# CSI_TX_IF0_VBUS2APB_WRAP_VBUSP_APB_CSI2TX register map
Vendor: Texas Instruments
Peripheral module from a debugger description file (folder J7ES).
Registers are 32-bit, read-write, reset 0x0 unless marked. A register's access mark holds for its fields unless they carry their own. Offsets are as the file gives them; lines under a group give offsets from that group; [hi:lo] are bit positions; {n}, {i} and the like mark numbered series; 'fields as' and 'values as' point back to an identical list; <NAME> marks a mode.

## CSI_TX_IF0_VBUS2APB_WRAP_VBUSP_APB_CSI2TX
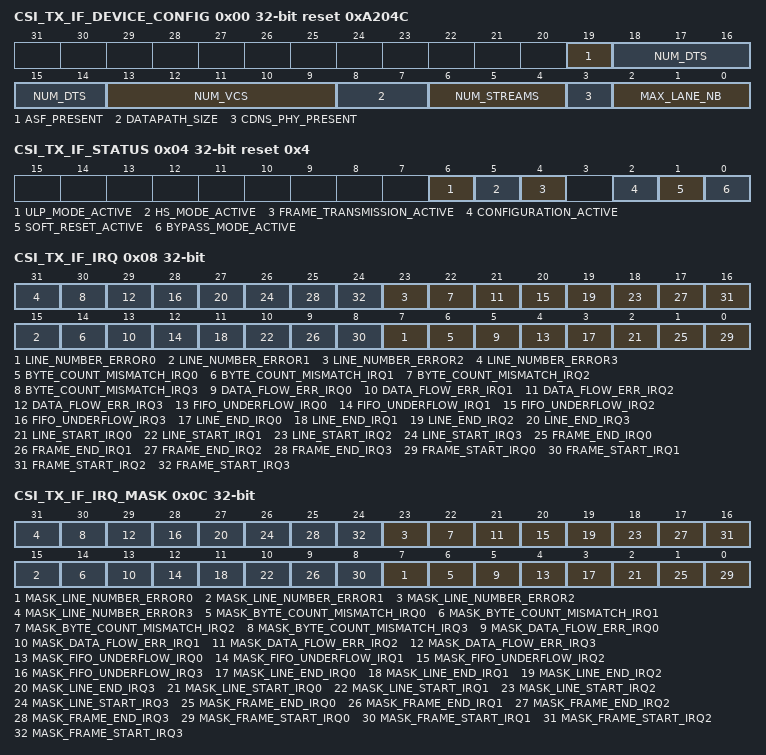
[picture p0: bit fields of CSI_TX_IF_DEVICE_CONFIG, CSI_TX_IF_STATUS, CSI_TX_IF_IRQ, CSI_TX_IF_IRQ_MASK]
0x00 CSI_TX_IF_DEVICE_CONFIG ro reset 0xA204C — CSI2 Transmitter Device Configuration Register
  [19] ASF_PRESENT — Active Internal Diagnostic Features:
  [18:14] NUM_DTS — Number of Datatypes DT_NUMBER=8
  [13:9] NUM_VCS — Number of Virtual Channels VC_NUMBER=16
  [8:7] DATAPATH_SIZE — Internal Datapath width
  [6:4] NUM_STREAMS — Number of Stream interfaces
  [3] CDNS_PHY_PRESENT — DPHY present
  [2:0] MAX_LANE_NB — Max Number of Lanes
0x04 CSI_TX_IF_STATUS ro reset 0x4 — CSI2 Transmitter Status Register
  [6] ULP_MODE_ACTIVE — Ultra Low Power Mode Active Flag When HIGH this bit indicates that ultra low power mode is active.
  [5] HS_MODE_ACTIVE — High Speed Mode Active Flag When HIGH this bit indicates that high speed mode is active.
  [4] FRAME_TRANSMISSION_ACTIVE — Frame Transmission Active Flag When HIGH this bit indicates that frame transmission is active.
  [2] CONFIGURATION_ACTIVE — Configuration Mode Active Flag When HIGH this bit indicates that the CSI2TX module is in the configuration mode.
  [1] SOFT_RESET_ACTIVE — Soft Reset Active Flag When HIGH this bit indicates that soft reset is active.
  [0] BYPASS_MODE_ACTIVE — Bypass Mode Active Flag When HIGH this bit indicates that bypass mode is active.
0x08 CSI_TX_IF_IRQ access not given — CSI2 Transmitter Interrupt Register. Write '1' to clear
  [8n+7] LINE_NUMBER_ERROR{n} (n=0..3) — Pixel IF {n} Line Number Error Flag - When HIGH this bit indicates that a line number error occurred. (access RW1C)
  [8n+6] BYTE_COUNT_MISMATCH_IRQ{n} (n=0..3) — Pixel IF {n} Byte Count Mismatch Flag - When HIGH this bit indicates that a byte count mismatch occurred. (access RW1C)
  [8n+5] DATA_FLOW_ERR_IRQ{n} (n=0..3) — Pixel IF {n} Data Flow Error Flag - When HIGH this bit indicates that data flow error has occurred, caused by the Frame/Line valid being asserted when the DPhy is not ready. (access RW1C)
  [8n+4] FIFO_UNDERFLOW_IRQ{n} (n=0..3) — Pixel IF {n} FIFO Underflow Flag - When HIGH this bit indicates that at least one internal FIFO underflow occurred. (access RW1C)
  [8n+3] LINE_END_IRQ{n} (n=0..3) — Pixel IF {n} Line End Flag - When HIGH this bit indicates that a line end occurred. (access RW1C)
  [8n+2] LINE_START_IRQ{n} (n=0..3) — Pixel IF {n} Line Start Flag - When HIGH this bit indicates that a line start occurred. (access RW1C)
  [8n+1] FRAME_END_IRQ{n} (n=0..3) — Pixel IF {n} Frame End Flag - When HIGH this bit indicates that a frame end occurred. (access RW1C)
  [8n] FRAME_START_IRQ{n} (n=0..3) — Pixel IF {n} Frame Start Flag - When HIGH this bit indicates that a frame start occurred. (access RW1C)
0x0C CSI_TX_IF_IRQ_MASK — CSI2 Transmitter Interrupt Mask Set Register
  [8n+7] MASK_LINE_NUMBER_ERROR{n} (n=0..3) — Pixel IF {n} Line Number Error Mask - Writing 1 to this bit enables interrupt generation from the line_number_error_irq bit.
  [8n+6] MASK_BYTE_COUNT_MISMATCH_IRQ{n} (n=0..3) — Pixel IF {n} Byte Count Mismatch Mask - Writing 1 to this bit enables interrupt generation from the byte_count_mismatch_irq bit.
  [8n+5] MASK_DATA_FLOW_ERR_IRQ{n} (n=0..3) — Pixel IF {n} FIFO Overflow Mask - Writing 1 to this bit enables interrupt generation from the data_flow_err_irq bit.
  [8n+4] MASK_FIFO_UNDERFLOW_IRQ{n} (n=0..3) — Pixel IF {n} FIFO Underflow Mask - Writing 1 to this bit enables interrupt generation from the fifo_underflow_irq bit.
  [8n+3] MASK_LINE_END_IRQ{n} (n=0..3) — Pixel IF {n} Line End Mask - Writing 1 to this bit enables interrupt generation from the line_en_irq bit.
  [8n+2] MASK_LINE_START_IRQ{n} (n=0..3) — Pixel IF {n} Line Start Mask - Writing 1 to this bit enables interrupt generation from the line_start_irq bit.
  [8n+1] MASK_FRAME_END_IRQ{n} (n=0..3) — Pixel IF {n} Frame End Mask - Writing 1 to this bit enables interrupt generation from the frame_end_irq bit.
  [8n] MASK_FRAME_START_IRQ{n} (n=0..3) — Pixel IF {n} Frame Start Mask - Writing 1 to this bit enables interrupt generation from the frame_start_irq bit.
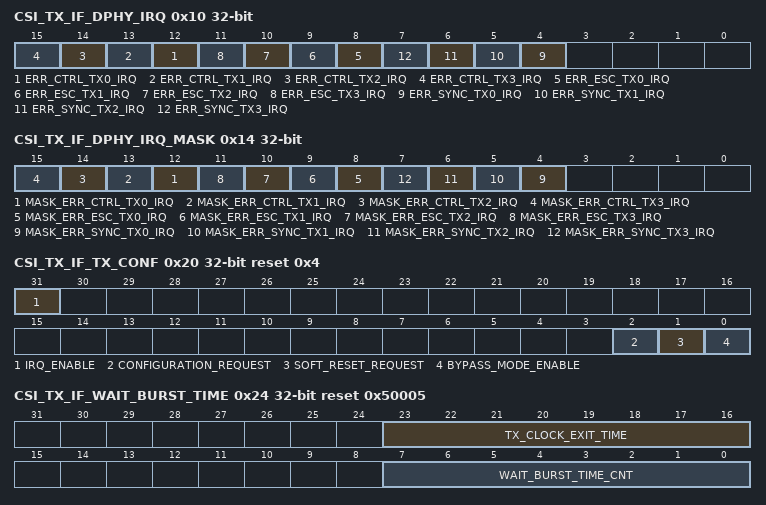
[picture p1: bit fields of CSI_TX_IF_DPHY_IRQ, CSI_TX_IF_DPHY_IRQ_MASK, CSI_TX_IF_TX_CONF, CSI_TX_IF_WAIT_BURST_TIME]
0x10 CSI_TX_IF_DPHY_IRQ access not given — DPHY Transmitter Interrupt Status. Level sensitive interrupt bits driven by DPHY signal pins. Write 1 to clear
  [n+12] ERR_CTRL_TX{n}_IRQ (n=0..3) — DPHY Transmitter Lane {n} ERR_CONTROL_IRQ (access RW1C)
  [n+8] ERR_ESC_TX{n}_IRQ (n=0..3) — DPHY Transmitter Lane {n} ERR_ESC_IRQ (access RW1C)
  [n+4] ERR_SYNC_TX{n}_IRQ (n=0..3) — DPHY Transmitter Lane {n} ERR_SYNC_ESC_IRQ (access RW1C)
0x14 CSI_TX_IF_DPHY_IRQ_MASK — DPHY Transmitter Interrupt Mask. Writing '1' to any bit enables interrupt generation when signal is set and interrupts are enabled.
  [n+12] MASK_ERR_CTRL_TX{n}_IRQ (n=0..3) — DPHY Transmitter Mask Lane {n} ERR_CONTROL_IRQ
  [n+8] MASK_ERR_ESC_TX{n}_IRQ (n=0..3) — DPHY Transmitter Mask Lane {n} ERR_ESC_IRQ
  [n+4] MASK_ERR_SYNC_TX{n}_IRQ (n=0..3) — DPHY Transmitter Mask Lane {n} ERR_SYNC_ESC_IRQ
0x20 CSI_TX_IF_TX_CONF reset 0x4 — CSI2 Transmitter Configuration Register
  [31] IRQ_ENABLE — Interrupt Enable - Writing 1 to this bit enables interrupts.
  [2] CONFIGURATION_REQUEST — Configuration Request - Writing 1 to this bit enables configuration mode.
  [1] SOFT_RESET_REQUEST — Soft Reset Request - Writing 1 to this bit enables soft reset.
  [0] BYPASS_MODE_ENABLE — Bypass Mode - Enable Writing 1 to this bit enables bypass mode.
0x24 CSI_TX_IF_WAIT_BURST_TIME reset 0x50005 — CSI2 Transmitter DPHY Wait Time configuration Register
  [23:16] TX_CLOCK_EXIT_TIME — Tx clock exit time - Number of tx_byte_clk cycles corresponding to the HS clock exit time.
  [7:0] WAIT_BURST_TIME_CNT — Wait Burst Time - Number of tx_byte_clk cycles corresponding to the inter HS burst gap.
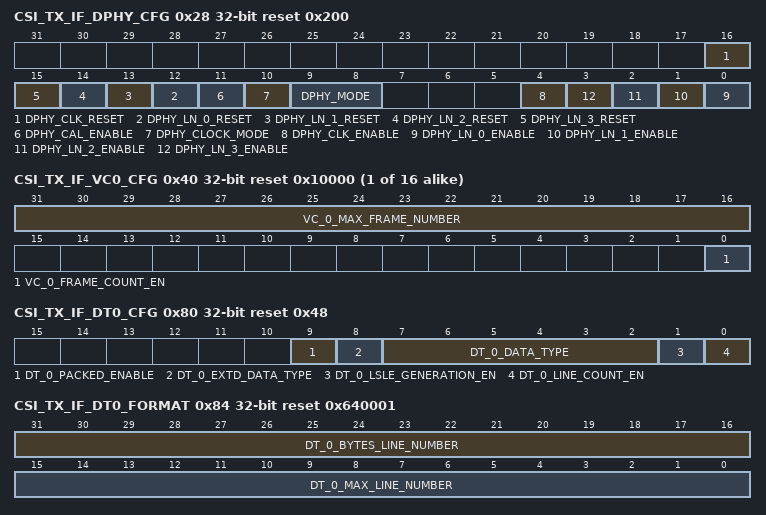
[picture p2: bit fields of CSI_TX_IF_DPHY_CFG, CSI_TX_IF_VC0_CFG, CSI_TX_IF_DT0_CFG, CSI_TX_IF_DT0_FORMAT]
0x28 CSI_TX_IF_DPHY_CFG reset 0x200 — CSI2 Transmitter DPHY Lane Enable configuration Register
  [16] DPHY_CLK_RESET — DPHY Clock Lane Reset - Active low reset for DPHY clock lane.
  [n+12] DPHY_LN_{n}_RESET (n=0..3) — DPHY Line 0 Reset - Active low reset for DPHY data lane {n}.
  [11] DPHY_CAL_ENABLE — DPHY Calibration Enable.
  [10] DPHY_CLOCK_MODE
  [9:8] DPHY_MODE
  [4] DPHY_CLK_ENABLE — DPHY Clock Lane - Active high enable for DPHY clock lane.
  [n] DPHY_LN_{n}_ENABLE (n=0..3) — DPHY Lane {n} Enable - Active high enable for DPHY data lane 0.
0x2C CSI_TX_IF_DPHY_CLK_WAKEUP reset 0x4E20 — CSI2 Transmitter DPHY Clock Lane wakeup time configuration Register
  [15:0] ULPS_CLK_LANE_WAKEUP — DPHY clock lane wakeup time in esc_clk cycles.
0x30 CSI_TX_IF_DPHY_ULPS_WAKEUP reset 0x4E20 — CSI2 Transmitter DPHY Data Lane wakeup time configuration Register
  [15:0] ULPS_DATA_LANE_WAKEUP — DPHY data lane wakeup time in in esc_clk cycles.
{0x40+4i} CSI_TX_IF_VC{i}_CFG reset 0x10000 (i=0..15) — CSI2 Transmitter Virtual Channel {i} Configuration Register
  [31:16] VC_{i}_MAX_FRAME_NUMBER — Max Frame Number - Maximum number of frames on Virtual Channel {i}.
  [0] VC_{i}_FRAME_COUNT_EN — Frame Count Enable - Writing 1 to this bit enables frame count on Virtual Channel {i}.
0x80 CSI_TX_IF_DT0_CFG reset 0x48 — CSI2 Transmitter Data Type 0 Configuration Register with pixel_dt_sel[:] = 0
  [9] DT_0_PACKED_ENABLE — Packed Enable - data stream is prepacked in to 32bit words on the pixel interface, the data is sent with the defined Data Type 0 with pixel_dt_sel[:] = 0.
  [8] DT_0_EXTD_DATA_TYPE — Extended Data Type - Type of data on Data Type 0 with pixel_dt_sel[:] = 0.
  [7:2] DT_0_DATA_TYPE — Data Type - Type of data on Data Type 0 with pixel_dt_sel[:] = 0.
  [1] DT_0_LSLE_GENERATION_EN — Line Start And Line End Short Packet Generation Enable - Writing 1 to this bit enables Line Start and Line End generation on Data Type 0.
  [0] DT_0_LINE_COUNT_EN — Line Count Enable - Writing 1 to this bit enables line count on Data Type 0.
0x84 CSI_TX_IF_DT0_FORMAT reset 0x640001 — CSI2 Transmitter Data Type 0 Format Register
  [31:16] DT_0_BYTES_LINE_NUMBER — Bytes Per Line - Bytes per line on Data Type 0 with pixel_dt_sel[:] = 0.
  [15:0] DT_0_MAX_LINE_NUMBER — Max Line Number - Maximum number of lines on Data Type 0 with pixel_dt_sel[:] = 0.
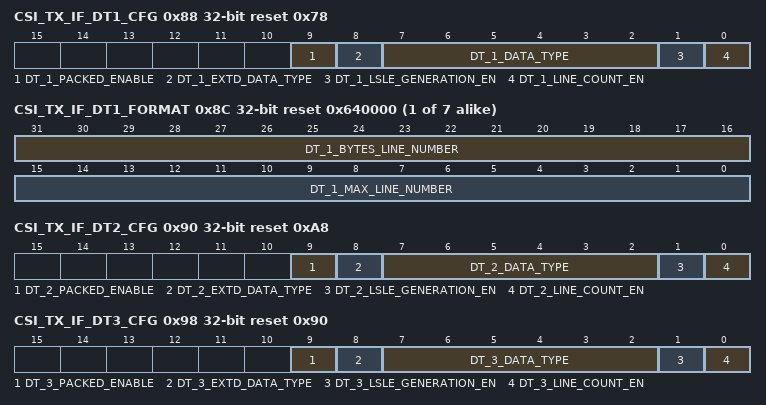
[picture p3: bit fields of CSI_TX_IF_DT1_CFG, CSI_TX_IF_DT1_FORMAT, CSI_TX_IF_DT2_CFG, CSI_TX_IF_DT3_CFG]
0x88 CSI_TX_IF_DT1_CFG reset 0x78 — CSI2 Transmitter Data Type 1 Configuration Register with pixel_dt_sel[:] = 1
  [9] DT_1_PACKED_ENABLE — Packed Enable - data stream is prepacked in to 32bit words on the pixel interface, the data is sent with the defined Data Type 1 with pixel_dt_sel[:] = 1.
  [8] DT_1_EXTD_DATA_TYPE — Extended Data Type - Type of data on Data Type 1 with pixel_dt_sel[:] = 1.
  [7:2] DT_1_DATA_TYPE — Data Type - Type of data on Data Type 1 with pixel_dt_sel[:] = 1.
  [1] DT_1_LSLE_GENERATION_EN — Line Start And Line End Short Packet Generation Enable - Writing 1 to this bit enables Line Start and Line End generation on Data Type 1.
  [0] DT_1_LINE_COUNT_EN — Line Count Enable - Writing 1 to this bit enables line count on Data Type 1.
{0x84+8i} CSI_TX_IF_DT{i}_FORMAT reset 0x640000 (i=1..7) — CSI2 Transmitter Data Type {i} Format Register
  [31:16] DT_{i}_BYTES_LINE_NUMBER — Bytes Per Line - Bytes per line on Data Type {i} with pixel_dt_sel[:] = {i}.
  [15:0] DT_{i}_MAX_LINE_NUMBER — Max Line Number - Maximum number of lines on Data Type {i} with pixel_dt_sel[:] = {i}.
0x90 CSI_TX_IF_DT2_CFG reset 0xA8 — CSI2 Transmitter Data Type 2 Configuration Register with pixel_dt_sel[:] = 2
  [9] DT_2_PACKED_ENABLE — Packed Enable - data stream is prepacked in to 32bit words on the pixel interface, the data is sent with the defined Data Type 2 with pixel_dt_sel[:] = 2.
  [8] DT_2_EXTD_DATA_TYPE — Extended Data Type - Type of data on Data Type 2 with pixel_dt_sel[:] = 2.
  [7:2] DT_2_DATA_TYPE — Data Type - Type of data on Data Type 2 with pixel_dt_sel[:] = 2.
  [1] DT_2_LSLE_GENERATION_EN — Line Start And Line End Short Packet Generation Enable - Writing 1 to this bit enables Line Start and Line End generation on Data Type 2.
  [0] DT_2_LINE_COUNT_EN — Line Count Enable - Writing 1 to this bit enables line count on Data Type 2.
0x98 CSI_TX_IF_DT3_CFG reset 0x90 — CSI2 Transmitter Data Type 3 Configuration Register with pixel_dt_sel[:] = 3
  [9] DT_3_PACKED_ENABLE — Packed Enable - data stream is prepacked in to 32bit words on the pixel interface, the data is sent with the defined Data Type 3 with pixel_dt_sel[:] = 3.
  [8] DT_3_EXTD_DATA_TYPE — Extended Data Type - Type of data on Data Type 3 with pixel_dt_sel[:] = 3.
  [7:2] DT_3_DATA_TYPE — Data Type - Type of data on Data Type 3 with pixel_dt_sel[:] = 3.
  [1] DT_3_LSLE_GENERATION_EN — Line Start And Line End Short Packet Generation Enable - Writing 1 to this bit enables Line Start and Line End generation on Data Type 3.
  [0] DT_3_LINE_COUNT_EN — Line Count Enable - Writing 1 to this bit enables line count on Data Type 3.
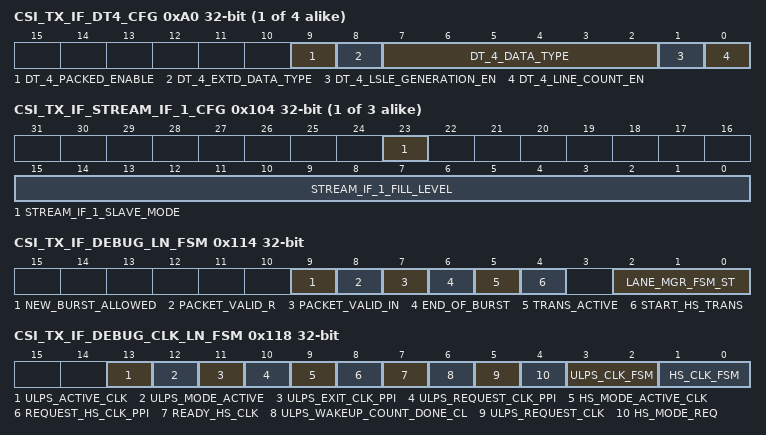
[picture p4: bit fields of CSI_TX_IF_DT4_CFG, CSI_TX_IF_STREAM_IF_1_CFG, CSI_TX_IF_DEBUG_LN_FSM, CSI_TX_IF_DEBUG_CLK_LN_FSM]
{0x80+8i} CSI_TX_IF_DT{i}_CFG (i=4..7) — CSI2 Transmitter Data Type {i} Configuration Register with pixel_dt_sel[:] = {i}
  [9] DT_{i}_PACKED_ENABLE — Packed Enable - data stream is prepacked in to 32bit words on the pixel interface, the data is sent with the defined Data Type {i} with pixel_dt_sel[:] = {i}.
  [8] DT_{i}_EXTD_DATA_TYPE — Extended Data Type - Type of data on Data Type {i} with pixel_dt_sel[:] = {i}.
  [7:2] DT_{i}_DATA_TYPE
  [1] DT_{i}_LSLE_GENERATION_EN — Line Start And Line End Short Packet Generation Enable - Writing 1 to this bit enables Line Start and Line End generation on Data Type {i}.
  [0] DT_{i}_LINE_COUNT_EN — Line Count Enable - Writing 1 to this bit enables line count on Data Type {i}.
0x100 CSI_TX_IF_STREAM_IF_0_CFG — CSI2 Stream 0 Configuration Register
  [15:0] STREAM_IF_0_FILL_LEVEL — Fill Level - Minimum number of packed 32 words loaded into the stream fifo before Tx will start for Stream if 0.
{0x100+4i} CSI_TX_IF_STREAM_IF_{i}_CFG (i=1..3) — CSI2 Stream {i} Configuration Register
  [23] STREAM_IF_{i}_SLAVE_MODE — Stream Slave Mode suppresses frame start/end packets in stream {i}.
  [15:0] STREAM_IF_{i}_FILL_LEVEL — Fill Level - Minimum number of packed 32 words loaded into the stream fifo before Tx will start for Stream if {i}.
0x110 CSI_TX_IF_DEBUG_CFG — CSI2 Transmitter Debug Enable Register
  [0] DBG_EN — Debug Enable.
0x114 CSI_TX_IF_DEBUG_LN_FSM ro — Debug Register for Lane FSM.
  [9] NEW_BURST_ALLOWED — Lane Mangement FSM.
  [8] PACKET_VALID_R — Lane Mangement FSM.
  [7] PACKET_VALID_IN — Lane Mangement FSM.
  [6] END_OF_BURST — Lane Mangement FSM.
  [5] TRANS_ACTIVE — Lane Mangement FSM.
  [4] START_HS_TRANS — Lane Mangement FSM.
  [2:0] LANE_MGR_FSM_ST — Lane Mangement FSM.
0x118 CSI_TX_IF_DEBUG_CLK_LN_FSM ro — Debug Register for Clock Lane FSM
  [13] ULPS_ACTIVE_CLK — Clock Lane FSM.
  [12] ULPS_MODE_ACTIVE — Clock Lane FSM.
  [11] ULPS_EXIT_CLK_PPI — Clock Lane FSM.
  [10] ULPS_REQUEST_CLK_PPI — Clock Lane FSM.
  [9] HS_MODE_ACTIVE_CLK — Clock Lane FSM.
  [8] REQUEST_HS_CLK_PPI — Clock Lane FSM.
  [7] READY_HS_CLK — Clock Lane FSM.
  [6] ULPS_WAKEUP_COUNT_DONE_CL — Clock Lane FSM.
  [5] ULPS_REQUEST_CLK — Clock Lane FSM.
  [4] HS_MODE_REQ — Clock Lane FSM.
  [3:2] ULPS_CLK_FSM — Clock Lane FSM.
  [1:0] HS_CLK_FSM — Clock Lane FSM.
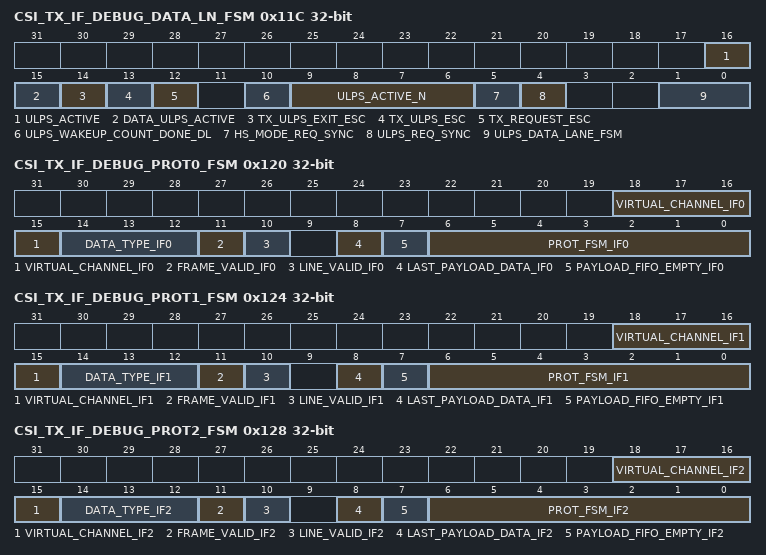
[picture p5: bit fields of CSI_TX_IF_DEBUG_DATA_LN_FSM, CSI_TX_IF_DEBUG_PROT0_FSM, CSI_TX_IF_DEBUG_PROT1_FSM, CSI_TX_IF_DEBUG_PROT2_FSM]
0x11C CSI_TX_IF_DEBUG_DATA_LN_FSM ro — Debug Register for Data Lane FSM.
  [16] ULPS_ACTIVE — Data Lane FSM.
  [15] DATA_ULPS_ACTIVE — Debug Register for Data Lane FSM.
  [14] TX_ULPS_EXIT_ESC — Data Lane FSM.
  [13] TX_ULPS_ESC — Data Lane FSM.
  [12] TX_REQUEST_ESC — Data Lane FSM.
  [10] ULPS_WAKEUP_COUNT_DONE_DL — Data Lane FSM.
  [9:6] ULPS_ACTIVE_N — Data Lane FSM.
  [5] HS_MODE_REQ_SYNC — Data Lane FSM.
  [4] ULPS_REQ_SYNC — Data Lane FSM.
  [1:0] ULPS_DATA_LANE_FSM — Data Lane FSM.
0x120 CSI_TX_IF_DEBUG_PROT0_FSM ro — Debug Register for Pixel IF0 Protocol FSM.
  [18:15] VIRTUAL_CHANNEL_IF0 — Pixel IF0 Protocol FSM.
  [14:12] DATA_TYPE_IF0 — Pixel IF0 Protocol FSM.
  [11] FRAME_VALID_IF0 — Pixel IF0 Protocol FSM.
  [10] LINE_VALID_IF0 — Pixel IF0 Protocol FSM.
  [8] LAST_PAYLOAD_DATA_IF0 — Pixel IF0 Protocol FSM.
  [7] PAYLOAD_FIFO_EMPTY_IF0 — Pixel IF0 Protocol FSM.
  [6:0] PROT_FSM_IF0 — Pixel IF0 Protocol FSM.
0x124 CSI_TX_IF_DEBUG_PROT1_FSM ro — Debug Register for Pixel IF1 Protocol FSM. (Optional: Available when PIXEL_IF2 or 4)
  [18:15] VIRTUAL_CHANNEL_IF1 — Pixel IF1 Protocol FSM.
  [14:12] DATA_TYPE_IF1 — Pixel IF1 Protocol FSM.
  [11] FRAME_VALID_IF1 — Pixel IF1 Protocol FSM.
  [10] LINE_VALID_IF1 — Pixel IF1 Protocol FSM.
  [8] LAST_PAYLOAD_DATA_IF1 — Pixel IF1 Protocol FSM.
  [7] PAYLOAD_FIFO_EMPTY_IF1 — Pixel IF1 Protocol FSM.
  [6:0] PROT_FSM_IF1 — Pixel IF1 Protocol FSM.
0x128 CSI_TX_IF_DEBUG_PROT2_FSM ro — Debug Register for Pixel IF2 Protocol FSM. (Optional: Available when PIXEL_IF4)
  [18:15] VIRTUAL_CHANNEL_IF2 — Pixel IF2 Protocol FSM.
  [14:12] DATA_TYPE_IF2 — Pixel IF2 Protocol FSM.
  [11] FRAME_VALID_IF2 — Pixel IF2 Protocol FSM.
  [10] LINE_VALID_IF2 — Pixel IF2 Protocol FSM.
  [8] LAST_PAYLOAD_DATA_IF2 — Pixel IF2 Protocol FSM.
  [7] PAYLOAD_FIFO_EMPTY_IF2 — Pixel IF2 Protocol FSM.
  [6:0] PROT_FSM_IF2 — Pixel IF2 Protocol FSM.
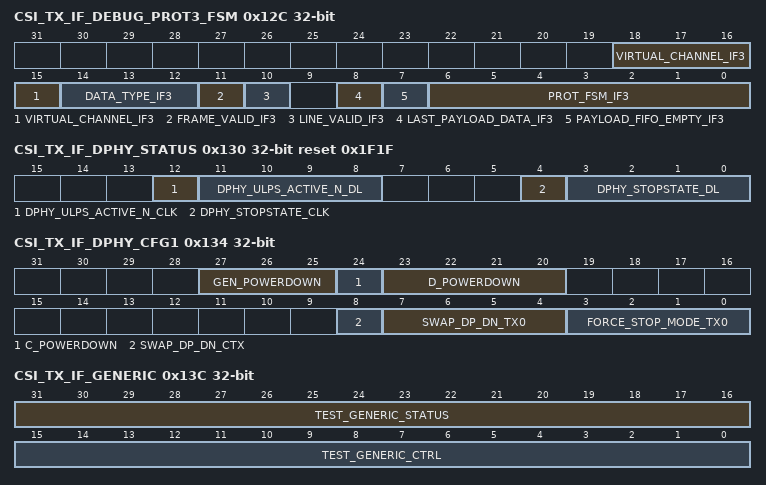
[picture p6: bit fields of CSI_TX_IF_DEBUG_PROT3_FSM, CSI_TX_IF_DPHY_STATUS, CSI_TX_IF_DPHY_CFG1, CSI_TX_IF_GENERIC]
0x12C CSI_TX_IF_DEBUG_PROT3_FSM ro — Debug Register for Pixel IF3 Protocol FSM. (Optional: Available when PIXEL_IF4)
  [18:15] VIRTUAL_CHANNEL_IF3 — Pixel IF3 Protocol FSM.
  [14:12] DATA_TYPE_IF3 — Pixel IF3 Protocol FSM.
  [11] FRAME_VALID_IF3 — Pixel IF3 Protocol FSM.
  [10] LINE_VALID_IF3 — Pixel IF3 Protocol FSM.
  [8] LAST_PAYLOAD_DATA_IF3 — Pixel IF3 Protocol FSM.
  [7] PAYLOAD_FIFO_EMPTY_IF3 — Pixel IF3 Protocol FSM.
  [6:0] PROT_FSM_IF3 — Pixel IF3 Protocol FSM.
0x130 CSI_TX_IF_DPHY_STATUS ro reset 0x1F1F — DPHY Transmitter Status.
  [12] DPHY_ULPS_ACTIVE_N_CLK — DPHY Transmitter ULPS_ACTIVE_N Clock Lane Status.
  [11:8] DPHY_ULPS_ACTIVE_N_DL — DPHY Transmitter ULPS_ACTIVE_N Data Lane
  [4] DPHY_STOPSTATE_CLK — DPHY Transmitter STOP_STATE Clock Lane Status.
  [3:0] DPHY_STOPSTATE_DL — DPHY Transmitter STOP_STATE Data Lane
0x134 CSI_TX_IF_DPHY_CFG1 — DPHY Transmitter Configuration.
  [27:25] GEN_POWERDOWN — DPHY Transmitter Power Down Common Module
  [24] C_POWERDOWN — DPHY Transmitter Power Down TX Clock
  [23:20] D_POWERDOWN — DPHY Transmitter Power Down TX Data Lanes
  [8] SWAP_DP_DN_CTX — DPHY Transmitter Swap DP_DN on Clock Lane
  [7:4] SWAP_DP_DN_TX0 — DPHY Transmitter Swap DP_DN on TX Data Lanes
  [3:0] FORCE_STOP_MODE_TX0 — DPHY Transmitter FORCE_STOP_MODE TX Data Lanes
0x13C CSI_TX_IF_GENERIC access per field — CSI2 Transmitter Test Register.
  [31:16] TEST_GENERIC_STATUS ro — CSI2 Transmitter Test Generic Status signals.
  [15:0] TEST_GENERIC_CTRL rw — CSI2 Transmitter Test Generic Control signals.
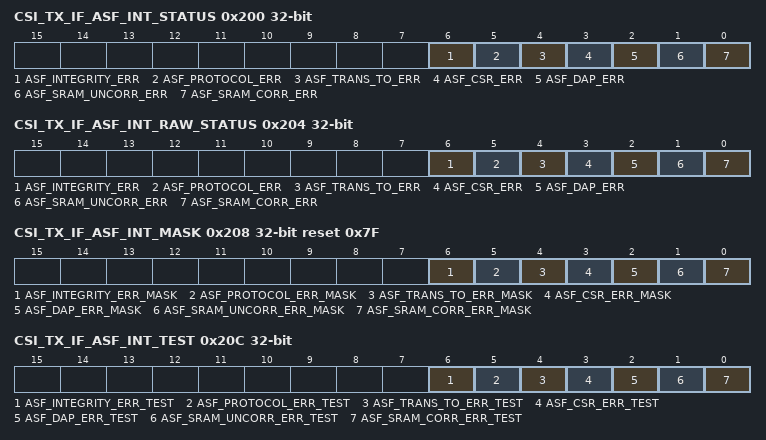
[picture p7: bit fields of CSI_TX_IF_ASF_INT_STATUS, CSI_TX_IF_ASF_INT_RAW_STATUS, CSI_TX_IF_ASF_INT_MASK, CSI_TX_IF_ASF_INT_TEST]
0x200 CSI_TX_IF_ASF_INT_STATUS access not given — ASF Interrupt Status Register. This register indicates the source of ASF interrupts. The corresponding bit in the mask register must be clear for a bit to be set. If any bit is set in this register the asf_int_fatal or asf_int_nonfatal signal will be asserted. Writing to either raw or masked registers, clear both registers. For test purposes, trigger signal interrupt event by writing to the ASF interrupt test register.
  [6] ASF_INTEGRITY_ERR — Integrity error interrupt (access RW1C)
  [5] ASF_PROTOCOL_ERR — Protocol error interrupt (access RW1C)
  [4] ASF_TRANS_TO_ERR — Transaction timeouts error interrupt (access RW1C)
  [3] ASF_CSR_ERR — Configuration and (access RW1C)
  [2] ASF_DAP_ERR — Data and address paths parity error interrupt (access RW1C)
  [1] ASF_SRAM_UNCORR_ERR — SRAM uncorrectable error interrupt (access RW1C)
  [0] ASF_SRAM_CORR_ERR — SRAM correctable error interrupt (access RW1C)
0x204 CSI_TX_IF_ASF_INT_RAW_STATUS access not given — ASF Interrupt Raw Status Register. A bit set in this raw register indicates a source of ASF fault in the corresponding feature. Writing to either raw or masked registers, clear both registers. For test purposes, trigger signal interrupt event by writing to the ASF interrupt test register.
  fields as CSI_TX_IF_ASF_INT_STATUS
0x208 CSI_TX_IF_ASF_INT_MASK access per field reset 0x7F — The ASF interrupt mask register indicating which interrupt bits in the ASF interrupt register are masked. All bits are set at reset. Clear the individual bit to enable the corresponding interrupt.
  [6] ASF_INTEGRITY_ERR_MASK rw — Mask bit for integrity error interrupt
  [5] ASF_PROTOCOL_ERR_MASK rw — Mask bit for protocol error interrupt.
  [4] ASF_TRANS_TO_ERR_MASK rw — Mask bit for transaction timeouts error interrupt.
  [3] ASF_CSR_ERR_MASK rw — Mask bit for configuration and
  [2] ASF_DAP_ERR_MASK rw — Mask bit for data and address paths parity error interrupt.
  [1] ASF_SRAM_UNCORR_ERR_MASK rw — Mask bit for SRAM uncorrectable error interrupt.
  [0] ASF_SRAM_CORR_ERR_MASK rw — Mask bit for SRAM correctable error interrupt.
0x20C CSI_TX_IF_ASF_INT_TEST access per field — The ASF interrupt test register emulate hardware even. Write one to individual bit to trigger single event in (masked and raw) registers according to mask and will generate interrupt accordingly.
  [6] ASF_INTEGRITY_ERR_TEST wo — Test bit for integrity error interrupt
  [5] ASF_PROTOCOL_ERR_TEST wo — Test bit for protocol error interrupt.
  [4] ASF_TRANS_TO_ERR_TEST wo — Test bit for transaction timeouts error interrupt.
  [3] ASF_CSR_ERR_TEST wo — Test bit for configuration and
  [2] ASF_DAP_ERR_TEST wo — Test bit for data and address paths parity error interrupt.
  [1] ASF_SRAM_UNCORR_ERR_TEST wo — Test bit for SRAM uncorrectable error interrupt.
  [0] ASF_SRAM_CORR_ERR_TEST wo — Test bit for SRAM correctable error interrupt.
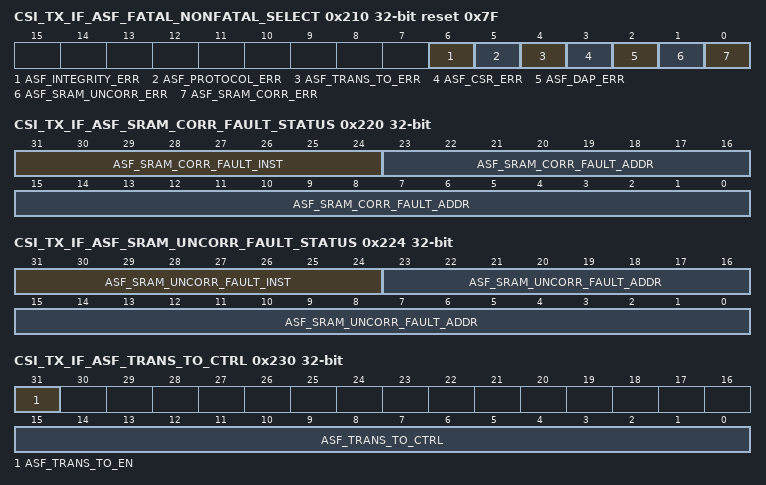
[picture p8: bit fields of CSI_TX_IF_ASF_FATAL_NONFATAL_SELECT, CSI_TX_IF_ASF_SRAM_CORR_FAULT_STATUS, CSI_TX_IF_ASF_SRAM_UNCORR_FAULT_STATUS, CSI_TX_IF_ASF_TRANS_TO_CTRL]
0x210 CSI_TX_IF_ASF_FATAL_NONFATAL_SELECT access per field reset 0x7F — The fatal or non-fatal interrupt register selects whether a fatal (asf_int_fatal) or non-fatal (asf_int_nonfatal) interrupt is triggered. If the bit of the event will be set to one then fatal interrupt (asf_int_fatal) will be triggered. Otherwise the non-fatal interrupt (asf_int_nonfatal) will be triggered.
  [6] ASF_INTEGRITY_ERR rw — Enable integrity error interrupt as fatal
  [5] ASF_PROTOCOL_ERR rw — Enable protocol error interrupt as fatal.
  [4] ASF_TRANS_TO_ERR rw — Enable transaction timeouts error interrupt as fatal.
  [3] ASF_CSR_ERR rw — Enable configuration and
  [2] ASF_DAP_ERR rw — Enable data and address paths parity error interrupt as fatal.
  [1] ASF_SRAM_UNCORR_ERR rw — Enable SRAM uncorrectable error interrupt as fatal.
  [0] ASF_SRAM_CORR_ERR rw — Enable SRAM correctable error interrupt as fatal.
0x220 CSI_TX_IF_ASF_SRAM_CORR_FAULT_STATUS ro — Status register for SRAM correctable fault. These fields are updated whenever asf_sram_corr_fault input is active.
  [31:24] ASF_SRAM_CORR_FAULT_INST — Last SRAM instance that generated fault.
  [23:0] ASF_SRAM_CORR_FAULT_ADDR — Last SRAM address that generated fault.
0x224 CSI_TX_IF_ASF_SRAM_UNCORR_FAULT_STATUS ro — Status register for SRAM uncorrectable fault. These fields are updated whenever asf_sram_uncorr_fault input is active.
  [31:24] ASF_SRAM_UNCORR_FAULT_INST — Last SRAM instance that generated fault.
  [23:0] ASF_SRAM_UNCORR_FAULT_ADDR — Last SRAM address that generated fault.
0x228 CSI_TX_IF_ASF_SRAM_FAULT_STATS access not given — Statistics register for SRAM faults. Note that this register clears when software writes to any field.
  [15:0] ASF_SRAM_FAULT_CORR_STATS — Count of number of correctable errors if implemented. (access RW1C)
0x230 CSI_TX_IF_ASF_TRANS_TO_CTRL — Control register to configure the ASF transaction timeout monitors.
  [31] ASF_TRANS_TO_EN — Enable transaction timeout monitoring.
  [15:0] ASF_TRANS_TO_CTRL — Timer value to use for transaction timeout monitor.
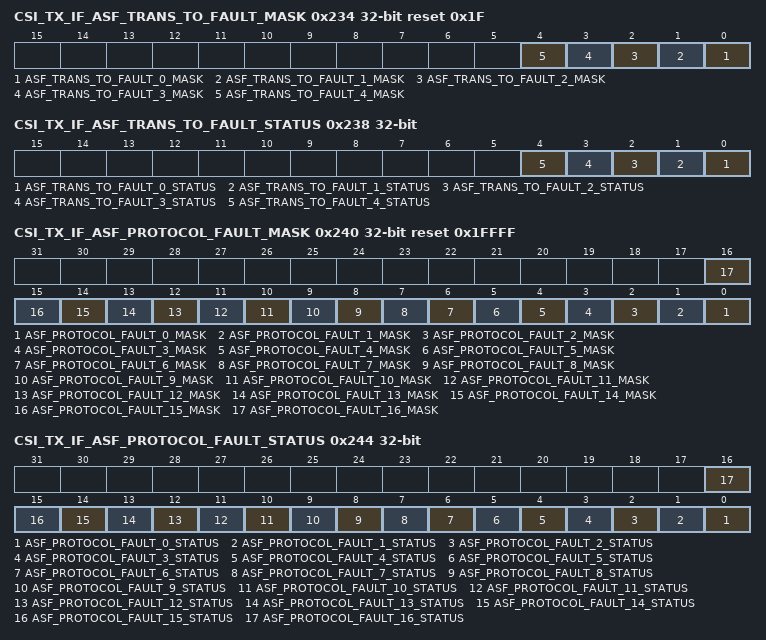
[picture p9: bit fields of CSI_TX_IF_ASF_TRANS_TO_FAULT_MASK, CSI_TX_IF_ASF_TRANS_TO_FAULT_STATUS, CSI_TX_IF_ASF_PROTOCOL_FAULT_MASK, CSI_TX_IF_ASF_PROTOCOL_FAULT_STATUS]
0x234 CSI_TX_IF_ASF_TRANS_TO_FAULT_MASK reset 0x1F — Control register to mask out ASF transaction timeout faults from triggering interrupts. On reset, all bits are set to mask out all sources. Clear the corresponding bit to enable the interrupt source. The width of this field is parameterisable and the bit definitions are implementation specific.
  [n] ASF_TRANS_TO_FAULT_{n}_MASK (n=0..4) — Mask register for each ASF transaction timeout fault source.
0x238 CSI_TX_IF_ASF_TRANS_TO_FAULT_STATUS access not given — Status register for transaction timeouts fault. If a fault occurs the revelant bit will be set to 1. Each bit can be cleared by software writing 1 to each bit.
  [n] ASF_TRANS_TO_FAULT_{n}_STATUS (n=0..4) — Status bits for transaction timeouts faults. (access RW1C)
0x240 CSI_TX_IF_ASF_PROTOCOL_FAULT_MASK reset 0x1FFFF — Control register to mask out ASF Protocol faults from triggering interrupts. On reset, all bits are set to mask out all sources. Clear the corresponding bit to enable the interrupt source. The width of this field is parameterisable and the bit definitions are implementation specific.
  [n] ASF_PROTOCOL_FAULT_{n}_MASK (n=0..16) — Mask register for each ASF protocol fault source.
0x244 CSI_TX_IF_ASF_PROTOCOL_FAULT_STATUS access not given — Status register for protocol faults. If a fault occurs the revelant bit will be set to 1. Each bit can be cleared by software writing 1 to each bit
  [n] ASF_PROTOCOL_FAULT_{n}_STATUS (n=0..16) — Status bits for protocol faults. (access RW1C)
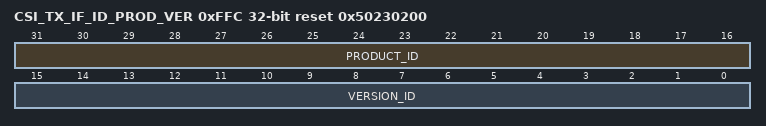
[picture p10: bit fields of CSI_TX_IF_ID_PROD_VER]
0xFFC CSI_TX_IF_ID_PROD_VER ro reset 0x50230200 — CSI2 Transmitter Product ID and Version Register. This register is hard-coded in order to allow software to identify the product and its release version. The product ID will be fixed for all versions, while the version will be updated as new releases for the same product are made.
  [31:16] PRODUCT_ID — CSI2 Transmitter Product Identification Number.
  [15:0] VERSION_ID — CSI2 Transmitter Product Version Number.
